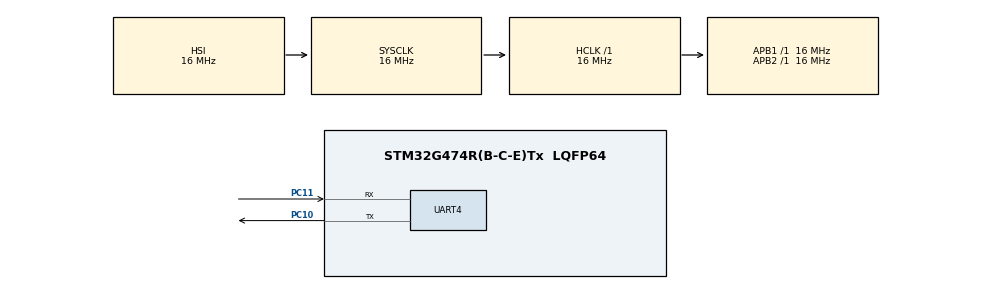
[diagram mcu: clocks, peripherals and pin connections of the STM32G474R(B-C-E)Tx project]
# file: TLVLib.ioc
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Mcu.Family=STM32G4
Mcu.Name=STM32G474R(B-C-E)Tx
Mcu.Package=LQFP64
NVIC.PriorityGroup=NVIC_PRIORITYGROUP_4
NVIC.UART4_IRQn=true\:0\:0\:false\:false\:true\:true\:true\:true
PC10.Mode=Asynchronous
PC10.Signal=UART4_TX
PC11.Mode=Asynchronous
PC11.Signal=UART4_RX
ProjectManager.HeapSize=0x200
ProjectManager.StackSize=0x400
ProjectManager.TargetToolchain=CMake
RCC.AHBFreq_Value=16000000
RCC.APB1Freq_Value=16000000
RCC.APB1TimFreq_Value=16000000
RCC.APB2Freq_Value=16000000
RCC.APB2TimFreq_Value=16000000
RCC.CortexFreq_Value=16000000
RCC.EXTERNAL_CLOCK_VALUE=12288000
RCC.HCLKFreq_Value=16000000
RCC.HSE_VALUE=8000000
RCC.HSI48_VALUE=48000000
RCC.HSI_VALUE=16000000
RCC.LSE_VALUE=32768
RCC.SYSCLKFreq_VALUE=16000000
RCC.USBFreq_Value=64000000
RCC.VCOOutputFreq_Value=128000000
VP_SYS_VS_DBSignals.Mode=DisableDeadBatterySignals
board=custom

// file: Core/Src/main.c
/* USER CODE BEGIN Header */
/**
 ******************************************************************************
 * @file           : main.c
 * @brief          : Main program body
 ******************************************************************************
 * @attention
 *
 * Copyright (c) 2026 STMicroelectronics.
 * All rights reserved.
 *
 * This software is licensed under terms that can be found in the LICENSE file
 * in the root directory of this software component.
 * If no LICENSE file comes with this software, it is provided AS-IS.
 *
 ******************************************************************************
 */
/* USER CODE END Header */
#include "main.h"
#include "app.h"

UART_HandleTypeDef huart4;

void SystemClock_Config(void);
static void MX_GPIO_Init(void);
static void MX_UART4_Init(void);

int main(void) {

  /* MCU Configuration--------------------------------------------------------*/

  /* Reset of all peripherals, Initializes the Flash interface and the Systick.
   */
  HAL_Init();

  /* Configure the system clock */
  SystemClock_Config();

  /* Initialize all configured peripherals */
  MX_GPIO_Init();
  MX_UART4_Init();
  /* USER CODE BEGIN 2 */
  app_init();
  /* USER CODE END 2 */

  /* Infinite loop */
  /* USER CODE BEGIN WHILE */
  while (1) {
    app_loop();
    /* USER CODE END WHILE */

  }
}

void SystemClock_Config(void) {
  RCC_OscInitTypeDef RCC_OscInitStruct = {0};
  RCC_ClkInitTypeDef RCC_ClkInitStruct = {0};

  /** Configure the main internal regulator output voltage
   */
  HAL_PWREx_ControlVoltageScaling(PWR_REGULATOR_VOLTAGE_SCALE1);

  /** Initializes the RCC Oscillators according to the specified parameters
   * in the RCC_OscInitTypeDef structure.
   */
  RCC_OscInitStruct.OscillatorType = RCC_OSCILLATORTYPE_HSI;
  RCC_OscInitStruct.HSIState = RCC_HSI_ON;
  RCC_OscInitStruct.HSICalibrationValue = RCC_HSICALIBRATION_DEFAULT;
  RCC_OscInitStruct.PLL.PLLState = RCC_PLL_NONE;
  if (HAL_RCC_OscConfig(&RCC_OscInitStruct) != HAL_OK) {
    Error_Handler();
  }

  /** Initializes the CPU, AHB and APB buses clocks
   */
  RCC_ClkInitStruct.ClockType = RCC_CLOCKTYPE_HCLK | RCC_CLOCKTYPE_SYSCLK |
                                RCC_CLOCKTYPE_PCLK1 | RCC_CLOCKTYPE_PCLK2;
  RCC_ClkInitStruct.SYSCLKSource = RCC_SYSCLKSOURCE_HSI;
  RCC_ClkInitStruct.AHBCLKDivider = RCC_SYSCLK_DIV1;
  RCC_ClkInitStruct.APB1CLKDivider = RCC_HCLK_DIV1;
  RCC_ClkInitStruct.APB2CLKDivider = RCC_HCLK_DIV1;

  if (HAL_RCC_ClockConfig(&RCC_ClkInitStruct, FLASH_LATENCY_0) != HAL_OK) {
    Error_Handler();
  }
}

static void MX_UART4_Init(void) {

  huart4.Instance = UART4;
  huart4.Init.BaudRate = 115200;
  huart4.Init.WordLength = UART_WORDLENGTH_8B;
  huart4.Init.StopBits = UART_STOPBITS_1;
  huart4.Init.Parity = UART_PARITY_NONE;
  huart4.Init.Mode = UART_MODE_TX_RX;
  huart4.Init.HwFlowCtl = UART_HWCONTROL_NONE;
  huart4.Init.OverSampling = UART_OVERSAMPLING_16;
  huart4.Init.OneBitSampling = UART_ONE_BIT_SAMPLE_DISABLE;
  huart4.Init.ClockPrescaler = UART_PRESCALER_DIV1;
  huart4.AdvancedInit.AdvFeatureInit = UART_ADVFEATURE_NO_INIT;
  if (HAL_UART_Init(&huart4) != HAL_OK) {
    Error_Handler();
  }
  if (HAL_UARTEx_SetTxFifoThreshold(&huart4, UART_TXFIFO_THRESHOLD_1_8) !=
      HAL_OK) {
    Error_Handler();
  }
  if (HAL_UARTEx_SetRxFifoThreshold(&huart4, UART_RXFIFO_THRESHOLD_1_8) !=
      HAL_OK) {
    Error_Handler();
  }
  if (HAL_UARTEx_DisableFifoMode(&huart4) != HAL_OK) {
    Error_Handler();
  }
}

static void MX_GPIO_Init(void) {

  /* GPIO Ports Clock Enable */
  __HAL_RCC_GPIOC_CLK_ENABLE();

}

void Error_Handler(void) {
  __disable_irq();
  while (1) {
  }
}
#ifdef USE_FULL_ASSERT
/**
 * @brief  Reports the name of the source file and the source line number
 *         where the assert_param error has occurred.
 * @param  file: pointer to the source file name
 * @param  line: assert_param error line source number
 * @retval None
 */
void assert_failed(uint8_t *file, uint32_t line) {
  /* USER CODE BEGIN 6 */
  /* User can add his own implementation to report the file name and line
     number, ex: printf("Wrong parameters value: file %s on line %d\r\n", file,
     line) */
  /* USER CODE END 6 */
}
#endif /* USE_FULL_ASSERT */
